# PIC16F1829 register map
File version: 1.0
Registers are 8-bit, read-write, reset 0x0 unless marked. A register's access mark holds for its fields unless they carry their own. Offsets are from the block's base; [hi:lo] are bit positions; {n}, {i} and the like mark numbered series.

## OSCILLATOR
Base 0x00800098
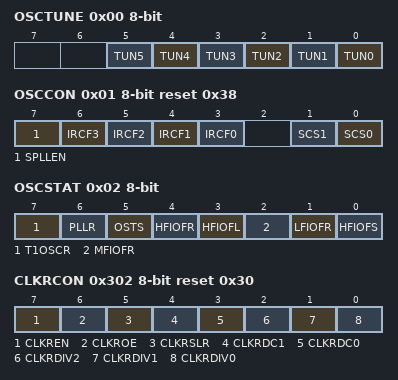
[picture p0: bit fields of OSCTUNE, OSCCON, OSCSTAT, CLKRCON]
0x00 OSCTUNE — OSCTUNE, data address 0x098
  [n] TUN{n} (n=0..5)
0x01 OSCCON reset 0x38 — OSCCON, data address 0x099
  [7] SPLLEN, [n+3] IRCF{n} (n=0..3), [1] SCS1, [0] SCS0
0x02 OSCSTAT (reset mask 0xDB) — OSCSTAT, data address 0x09a
  [7] T1OSCR, [6] PLLR, [5] OSTS, [4] HFIOFR, [3] HFIOFL, [2] MFIOFR, [1] LFIOFR, [0] HFIOFS
0x302 CLKRCON reset 0x30 — CLKRCON, data address 0x39a
  [7] CLKREN, [6] CLKROE, [5] CLKRSLR, [4] CLKRDC1, [3] CLKRDC0, [2] CLKRDIV2, [1] CLKRDIV1, [0] CLKRDIV0

## PORTA
Base 0x0080000C
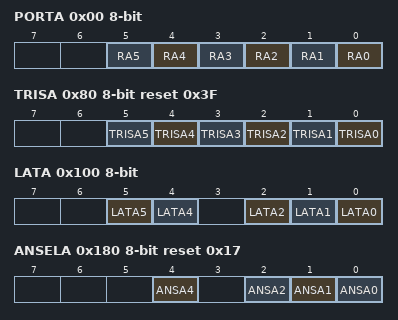
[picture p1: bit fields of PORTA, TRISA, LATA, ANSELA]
0x00 PORTA reset not defined — PORTA, data address 0x00c
  [n] RA{n} (n=0..5)
0x80 TRISA reset 0x3F — TRISA, data address 0x08c
  [n] TRISA{n} (n=0..5)
0x100 LATA reset not defined — LATA, data address 0x10c
  [5] LATA5, [4] LATA4, [2] LATA2, [1] LATA1, [0] LATA0
0x180 ANSELA reset 0x17 — ANSELA, data address 0x18c
  [4] ANSA4, [2] ANSA2, [1] ANSA1, [0] ANSA0
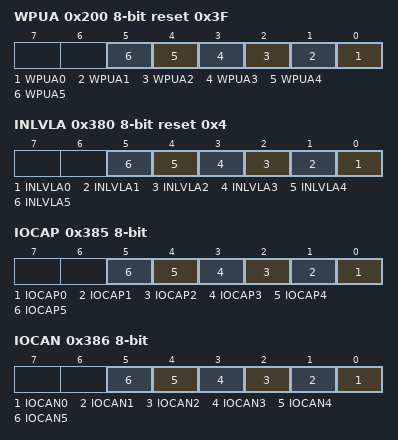
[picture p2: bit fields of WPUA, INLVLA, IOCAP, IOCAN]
0x200 WPUA reset 0x3F — WPUA, data address 0x20c
  [n] WPUA{n} (n=0..5)
0x380 INLVLA reset 0x4 — INLVLA, data address 0x38c
  [n] INLVLA{n} (n=0..5)
0x385 IOCAP — IOCAP, data address 0x391
  [n] IOCAP{n} (n=0..5)
0x386 IOCAN — IOCAN, data address 0x392
  [n] IOCAN{n} (n=0..5)
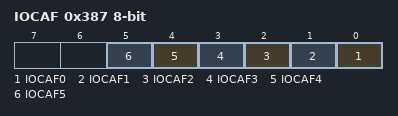
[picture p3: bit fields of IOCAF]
0x387 IOCAF — IOCAF, data address 0x393
  [n] IOCAF{n} (n=0..5)

## PORTB
Base 0x0080000D
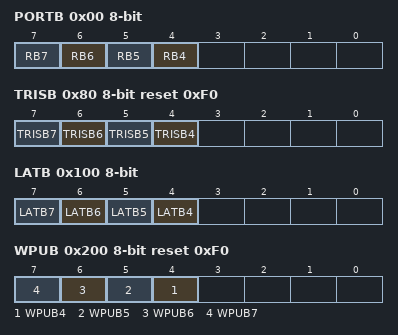
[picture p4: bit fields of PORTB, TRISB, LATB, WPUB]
0x00 PORTB reset not defined — PORTB, data address 0x00d
  [n] RB{n} (n=4..7)
0x80 TRISB reset 0xF0 — TRISB, data address 0x08d
  [n] TRISB{n} (n=4..7)
0x100 LATB reset not defined — LATB, data address 0x10d
  [n] LATB{n} (n=4..7)
0x180 ANSELB reset 0x30 — ANSELB, data address 0x18d
  [5:4] ANSELB
0x200 WPUB reset 0xF0 — WPUB, data address 0x20d
  [n] WPUB{n} (n=4..7)
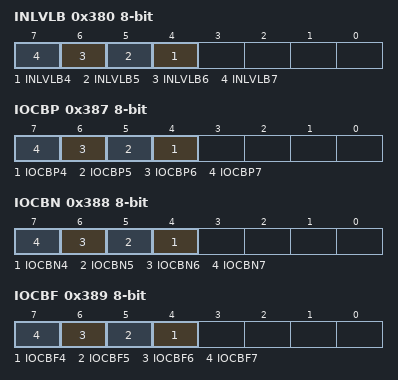
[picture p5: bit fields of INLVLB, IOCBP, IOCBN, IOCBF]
0x380 INLVLB — INLVLB, data address 0x38d
  [n] INLVLB{n} (n=4..7)
0x387 IOCBP — IOCBP, data address 0x394
  [n] IOCBP{n} (n=4..7)
0x388 IOCBN — IOCBN, data address 0x395
  [n] IOCBN{n} (n=4..7)
0x389 IOCBF — IOCBF, data address 0x396
  [n] IOCBF{n} (n=4..7)

## PORTC
Base 0x0080000E
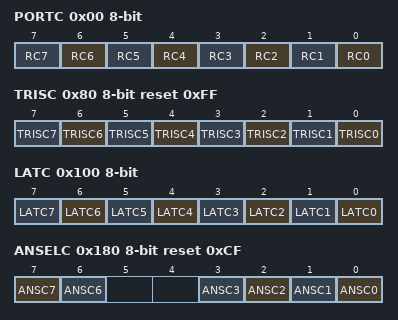
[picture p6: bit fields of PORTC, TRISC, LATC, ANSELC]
0x00 PORTC reset not defined — PORTC, data address 0x00e
  [n] RC{n} (n=0..7)
0x80 TRISC reset 0xFF — TRISC, data address 0x08e
  [n] TRISC{n} (n=0..7)
0x100 LATC reset not defined — LATC, data address 0x10e
  [n] LATC{n} (n=0..7)
0x180 ANSELC reset 0xCF — ANSELC, data address 0x18e
  [7] ANSC7, [6] ANSC6, [n] ANSC{n} (n=0..3)
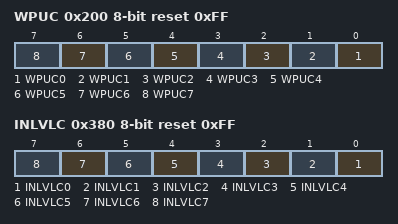
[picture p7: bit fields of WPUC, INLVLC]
0x200 WPUC reset 0xFF — WPUC, data address 0x20e
  [n] WPUC{n} (n=0..7)
0x380 INLVLC reset 0xFF — INLVLC, data address 0x38e
  [n] INLVLC{n} (n=0..7)

## REFERENCES — Voltage reference, DAC and SR latch
Base 0x00800117
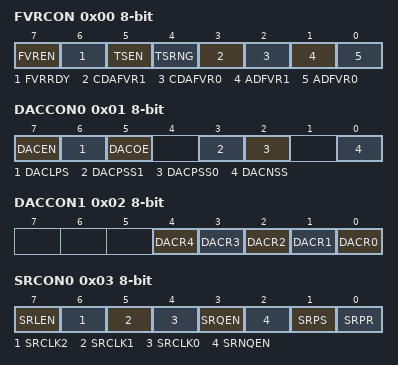
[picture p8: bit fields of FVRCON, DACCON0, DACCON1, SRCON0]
0x00 FVRCON (reset mask 0xBF) — FVRCON, data address 0x117
  [7] FVREN, [6] FVRRDY, [5] TSEN, [4] TSRNG, [3] CDAFVR1, [2] CDAFVR0, [1] ADFVR1, [0] ADFVR0
0x01 DACCON0 — DACCON0, data address 0x118
  [7] DACEN, [6] DACLPS, [5] DACOE, [3] DACPSS1, [2] DACPSS0, [0] DACNSS
0x02 DACCON1 — DACCON1, data address 0x119
  [n] DACR{n} (n=0..4)
0x03 SRCON0 — SRCON0, data address 0x11a
  [7] SRLEN, [6] SRCLK2, [5] SRCLK1, [4] SRCLK0, [3] SRQEN, [2] SRNQEN, [1] SRPS, [0] SRPR
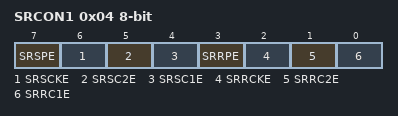
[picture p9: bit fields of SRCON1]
0x04 SRCON1 — SRCON1, data address 0x11b
  [7] SRSPE, [6] SRSCKE, [5] SRSC2E, [4] SRSC1E, [3] SRRPE, [2] SRRCKE, [1] SRRC2E, [0] SRRC1E

## SYSTEM — Reset, watchdog and pin options
Base 0x00800095
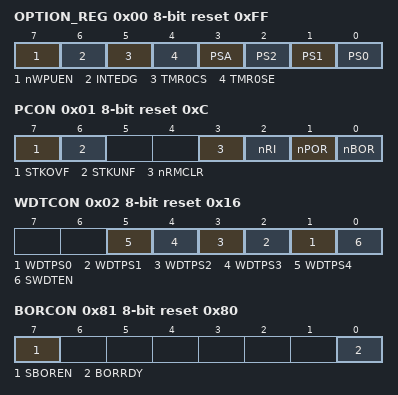
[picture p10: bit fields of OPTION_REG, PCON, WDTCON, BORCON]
0x00 OPTION_REG reset 0xFF — OPTION_REG, data address 0x095
  [7] nWPUEN, [6] INTEDG, [5] TMR0CS, [4] TMR0SE, [3] PSA, [2] PS2, [1] PS1, [0] PS0
0x01 PCON reset 0xC (reset mask 0xCC) — PCON, data address 0x096
  [7] STKOVF, [6] STKUNF, [3] nRMCLR, [2] nRI, [1] nPOR, [0] nBOR
0x02 WDTCON reset 0x16 — WDTCON, data address 0x097
  [n+1] WDTPS{n} (n=0..4), [0] SWDTEN
0x81 BORCON reset 0x80 (reset mask 0x80) — BORCON, data address 0x116
  [7] SBOREN, [0] BORRDY
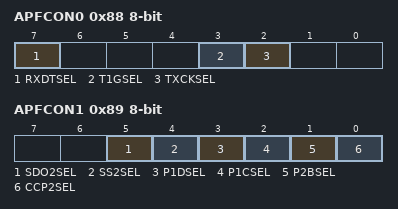
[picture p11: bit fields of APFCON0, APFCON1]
0x88 APFCON0 — APFCON0, data address 0x11d
  [7] RXDTSEL, [3] T1GSEL, [2] TXCKSEL
0x89 APFCON1 — APFCON1, data address 0x11e
  [5] SDO2SEL, [4] SS2SEL, [3] P1DSEL, [2] P1CSEL, [1] P2BSEL, [0] CCP2SEL

## TIMER0
Base 0x00800015
0x00 TMR0 reset not defined — TMR0, data address 0x015

## TIMER1
Base 0x00800016
0x00 TMR1L reset not defined — TMR1L, data address 0x016
0x01 TMR1H reset not defined — TMR1H, data address 0x017
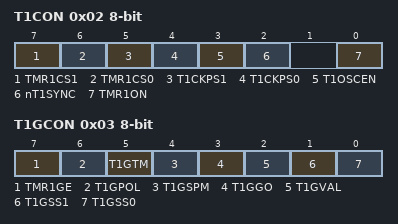
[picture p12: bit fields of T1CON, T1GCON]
0x02 T1CON — T1CON, data address 0x018
  [7] TMR1CS1, [6] TMR1CS0, [5] T1CKPS1, [4] T1CKPS0, [3] T1OSCEN, [2] nT1SYNC, [0] TMR1ON
0x03 T1GCON (reset mask 0xFB) — T1GCON, data address 0x019
  [7] TMR1GE, [6] T1GPOL, [5] T1GTM, [4] T1GSPM, [3] T1GGO, [2] T1GVAL, [1] T1GSS1, [0] T1GSS0

## TIMER2
Base 0x0080001A
0x00 TMR2 — TMR2, data address 0x01a
0x01 PR2 reset 0xFF — PR2, data address 0x01b
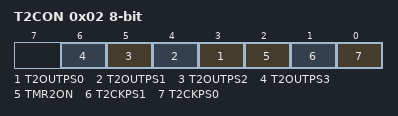
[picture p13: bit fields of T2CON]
0x02 T2CON — T2CON, data address 0x01c
  [n+3] T2OUTPS{n} (n=0..3), [2] TMR2ON, [1] T2CKPS1, [0] T2CKPS0

## TIMER4
Base 0x00800415
0x00 TMR4 — TMR4, data address 0x415
0x01 PR4 reset 0xFF — PR4, data address 0x416
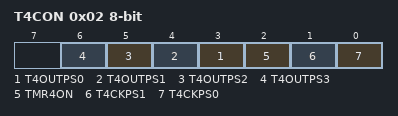
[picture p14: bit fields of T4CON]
0x02 T4CON — T4CON, data address 0x417
  [n+3] T4OUTPS{n} (n=0..3), [2] TMR4ON, [1] T4CKPS1, [0] T4CKPS0

## TIMER6
Base 0x0080041C
0x00 TMR6 — TMR6, data address 0x41c
0x01 PR6 reset 0xFF — PR6, data address 0x41d
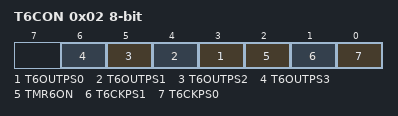
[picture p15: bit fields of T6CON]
0x02 T6CON — T6CON, data address 0x41e
  [n+3] T6OUTPS{n} (n=0..3), [2] TMR6ON, [1] T6CKPS1, [0] T6CKPS0

## OTHER — Other registers
Base 0x0080039C
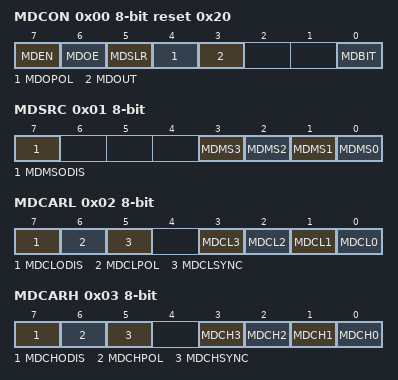
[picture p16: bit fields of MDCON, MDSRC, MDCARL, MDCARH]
0x00 MDCON reset 0x20 — MDCON, data address 0x39c
  [7] MDEN, [6] MDOE, [5] MDSLR, [4] MDOPOL, [3] MDOUT, [0] MDBIT
0x01 MDSRC reset not defined — MDSRC, data address 0x39d
  [7] MDMSODIS, [n] MDMS{n} (n=0..3)
0x02 MDCARL reset not defined — MDCARL, data address 0x39e
  [7] MDCLODIS, [6] MDCLPOL, [5] MDCLSYNC, [n] MDCL{n} (n=0..3)
0x03 MDCARH reset not defined — MDCARH, data address 0x39f
  [7] MDCHODIS, [6] MDCHPOL, [5] MDCHSYNC, [n] MDCH{n} (n=0..3)
